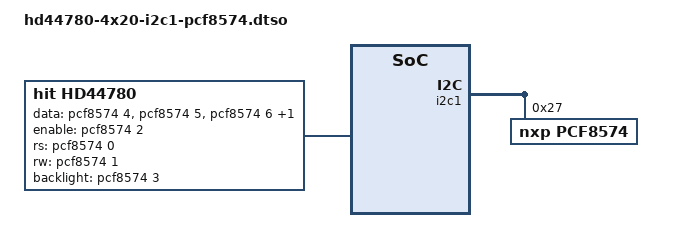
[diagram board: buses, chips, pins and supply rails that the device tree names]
// Use HD44780 LCD Display with PCF8574 I2C I/O expander on I2C-1
// The display has two lines with 16 chars each
// Note that on most boards another fragment must enable the I2C-1 Bus

/dts-v1/;
/plugin/;

/ {
	fragment@0 {
		target = <&i2c1>;
		__overlay__ {
			#address-cells = <1>;
			#size-cells = <0>;

			pcf8574: pcf8574@27 {
				compatible = "nxp,pcf8574";
				reg = <0x27>;
				gpio-controller;
				#gpio-cells = <2>;
			};
		};
	};

	fragment@1 {
		target-path = "/";
		__overlay__ {
			hd44780 {
				compatible = "hit,hd44780";
				display-height-chars = <4>;
				display-width-chars  = <20>;
				data-gpios = <&pcf8574 4 0>,
					     <&pcf8574 5 0>,
					     <&pcf8574 6 0>,
					     <&pcf8574 7 0>;
				enable-gpios = <&pcf8574 2 0>;
				rs-gpios = <&pcf8574 0 0>;
				rw-gpios = <&pcf8574 1 0>;
				backlight-gpios = <&pcf8574 3 0>;
			};
		};
	};
};
